# CH32M030 register map
Vendor: WCH Ltd.; File version: 1.1
Registers are 32-bit, read-write, reset 0x0 unless marked. A register's access mark holds for its fields unless they carry their own. Offsets are from the block's base; [hi:lo] are bit positions.

## RCC — Reset and clock control
Base 0x40021000
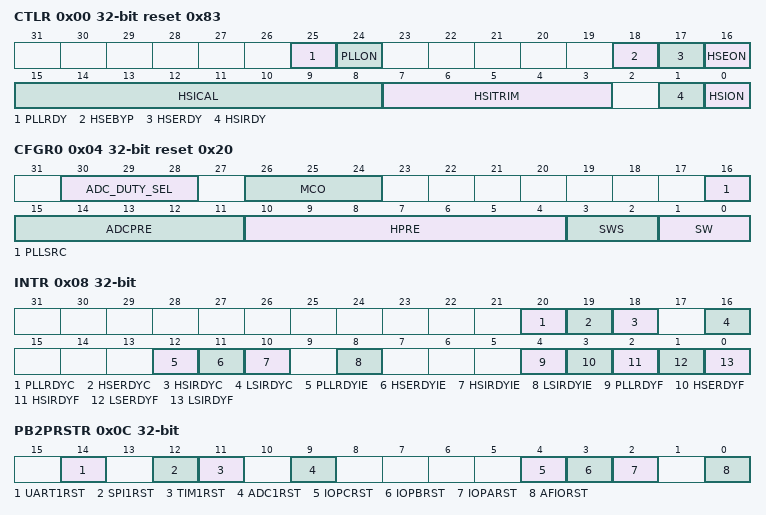
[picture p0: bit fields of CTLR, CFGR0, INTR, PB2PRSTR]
0x00 CTLR access per field reset 0x83 — Clock control register
  [25] PLLRDY ro — PLL clock ready flag
  [24] PLLON rw — PLL enable
  [18] HSEBYP rw — External High Speed clock Bypass
  [17] HSERDY ro — External High Speed clock ready flag
  [16] HSEON rw — External High Speed clock enable
  [15:8] HSICAL ro — Internal High Speed clock Calibration
  [7:3] HSITRIM rw — Internal High Speed clock trimming
  [1] HSIRDY ro — Internal High Speed clock ready flag
  [0] HSION rw — Internal High Speed clock enable
0x04 CFGR0 access per field reset 0x20 — Clock configuration register (RCC_CFGR0)
  [30:28] ADC_DUTY_SEL rw — ADC clock duty cycle Selection
  [26:24] MCO rw — Microcontroller clock output
  [16] PLLSRC rw — PLL entry clock source
  [15:11] ADCPRE rw — ADC prescaler
  [10:4] HPRE rw — HB prescaler
  [3:2] SWS ro — System Clock Switch Status
  [1:0] SW rw — System clock Switch
0x08 INTR access per field — Clock interrupt register (RCC_INTR)
  [20] PLLRDYC wo — PLL Ready Interrupt Clear
  [19] HSERDYC wo — HSE Ready Interrupt Clear
  [18] HSIRDYC wo — HSI Ready Interrupt Clear
  [16] LSIRDYC wo — LSI Ready Interrupt Clear
  [12] PLLRDYIE rw — PLL Ready Interrupt Enable
  [11] HSERDYIE rw — HSE Ready Interrupt Enable
  [10] HSIRDYIE rw — HSI Ready Interrupt Enable
  [8] LSIRDYIE rw — LSI Ready Interrupt Enable
  [4] PLLRDYF ro — PLL Ready Interrupt flag
  [3] HSERDYF ro — HSE Ready Interrupt flag
  [2] HSIRDYF ro — HSI Ready Interrupt flag
  [1] LSERDYF ro — LSE Ready Interrupt flag
  [0] LSIRDYF ro — LSI Ready Interrupt flag
0x0C PB2PRSTR — PB2 peripheral reset register (RCC_PB2PRSTR)
  [14] UART1RST — UART1 reset
  [12] SPI1RST — SPI1 reset
  [11] TIM1RST — TIM1 timer reset
  [9] ADC1RST — ADC 1 interface reset
  [4] IOPCRST — IO port C reset
  [3] IOPBRST — IO port B reset
  [2] IOPARST — IO port A reset
  [0] AFIORST — Alternate function I/O reset
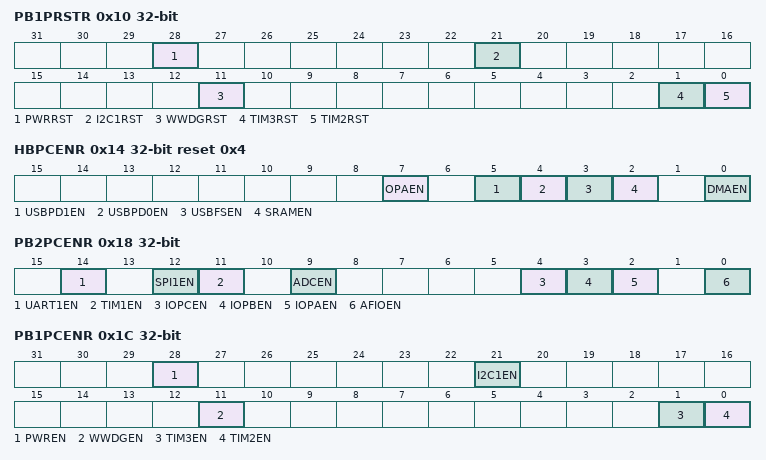
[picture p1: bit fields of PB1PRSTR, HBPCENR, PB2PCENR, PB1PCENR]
0x10 PB1PRSTR — PB1 peripheral reset register (RCC_PB1PRSTR)
  [28] PWRRST — Power interface reset
  [21] I2C1RST — I2C1 reset
  [11] WWDGRST — Window watchdog reset
  [1] TIM3RST — TIM3 reset
  [0] TIM2RST — TIM2 reset
0x14 HBPCENR reset 0x4 — HB Peripheral Clock enable register (RCC_HBPCENR)
  [7] OPAEN — OPA_CMP interface clock enable
  [5] USBPD1EN — USBPD1 interface clock enable
  [4] USBPD0EN — USBPD0 interface clock enable
  [3] USBFSEN — USBFS interface clock enable
  [2] SRAMEN — SRAM interface clock enable
  [0] DMAEN — DMA clock enable
0x18 PB2PCENR — PB2 peripheral clock enable register (RCC_PB2PCENR)
  [14] UART1EN — UART1 clock enable
  [12] SPI1EN — SPI1 clock enable
  [11] TIM1EN — TIM1 Timer clock enable
  [9] ADCEN — ADC interface clock enable
  [4] IOPCEN — I/O port C clock enable
  [3] IOPBEN — I/O port B clock enable
  [2] IOPAEN — I/O port A clock enable
  [0] AFIOEN — Alternate function I/O clock enable
0x1C PB1PCENR — PB1 peripheral clock enable register (RCC_PB1PCENR)
  [28] PWREN — Power interface clock enable
  [21] I2C1EN — I2C 1 clock enable
  [11] WWDGEN — Window watchdog clock enable
  [1] TIM3EN — Timer 3 clock enable
  [0] TIM2EN — Timer 2 clock enable
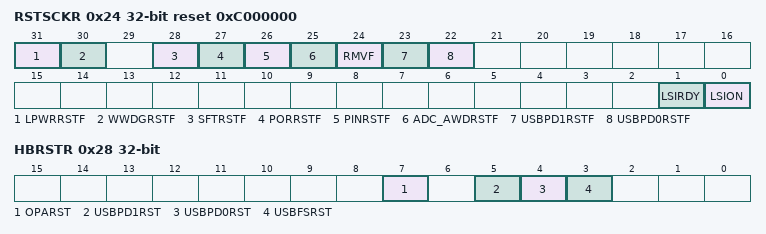
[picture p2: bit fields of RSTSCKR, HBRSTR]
0x24 RSTSCKR access per field reset 0xC000000 — Control/status register (RCC_RSTSCKR)
  [31] LPWRRSTF rw — Low-power reset flag
  [30] WWDGRSTF rw — Window watchdog reset flag
  [28] SFTRSTF rw — Software reset flag
  [27] PORRSTF rw — POR/PDR reset flag
  [26] PINRSTF rw — PIN reset flag
  [25] ADC_AWDRSTF rw — ADC analog watchdog reset flag
  [24] RMVF rw — Remove reset flag
  [23] USBPD1RSTF rw — USBPD1 reset flag
  [22] USBPD0RSTF rw — USBPD0 reset flag
  [1] LSIRDY ro — Internal low speed oscillator ready
  [0] LSION rw — Internal low speed oscillator enable
0x28 HBRSTR — HB reset register(RCC_APHBRSTR)
  [7] OPARST — OPA reset
  [5] USBPD1RST — USBPD1 reset
  [4] USBPD0RST — USBPD0 reset
  [3] USBFSRST — USBFS reset
